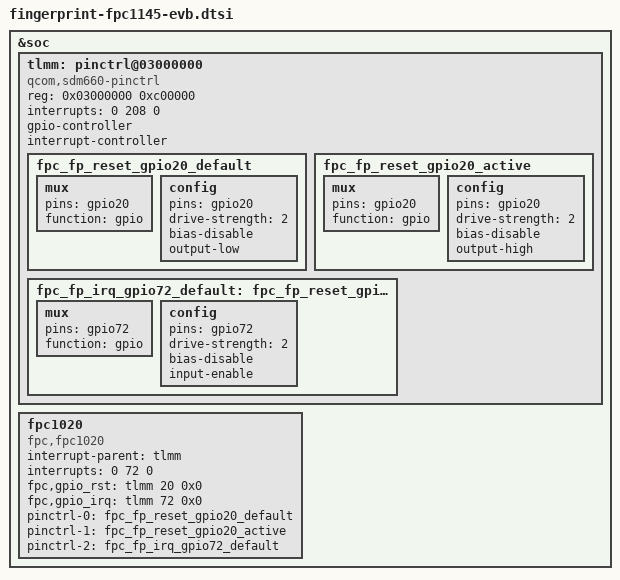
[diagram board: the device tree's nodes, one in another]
&soc {
	tlmm: pinctrl@03000000 {
		compatible = "qcom,sdm660-pinctrl";
		reg = <0x03000000 0xc00000>;
		interrupts = <0 208 0>;
		gpio-controller;
		#gpio-cells = <2>;
		interrupt-controller;
		#interrupt-cells = <2>;

		fpc_fp_reset_gpio20_default: fpc_fp_reset_gpio20_default {
			mux {
				pins = "gpio20";
				function = "gpio";
			};

			config {
				pins = "gpio20";
				drive-strength = <2>;
				bias-disable;
				output-low;
			};
		};

		fpc_fp_reset_gpio20_active: fpc_fp_reset_gpio20_active {
			mux {
				pins = "gpio20";
				function = "gpio";
			};

			config {
				pins = "gpio20";
				drive-strength = <2>;
				bias-disable;
				output-high;
			};
		};

		fpc_fp_irq_gpio72_default: fpc_fp_reset_gpio72_default {
			mux {
				pins = "gpio72";
				function = "gpio";
			};

			config {
				pins = "gpio72";
				drive-strength = <2>;
				bias-disable;
				input-enable;
			};
		};
	};

	fpc1020 {
		compatible = "fpc,fpc1020";
		status = "ok";
		interrupt-parent = <&tlmm>;
		interrupts = <0 72 0>;
		fpc,gpio_rst    = <&tlmm 20 0x0>;
		fpc,gpio_irq    = <&tlmm 72 0x0>;

		pinctrl-names = "fpc1020_reset_reset",
			"fpc1020_reset_active",
			"fpc1020_irq_active";

		pinctrl-0 = <&fpc_fp_reset_gpio20_default>;
		pinctrl-1 = <&fpc_fp_reset_gpio20_active>;
		pinctrl-2 = <&fpc_fp_irq_gpio72_default>;
	};
};
